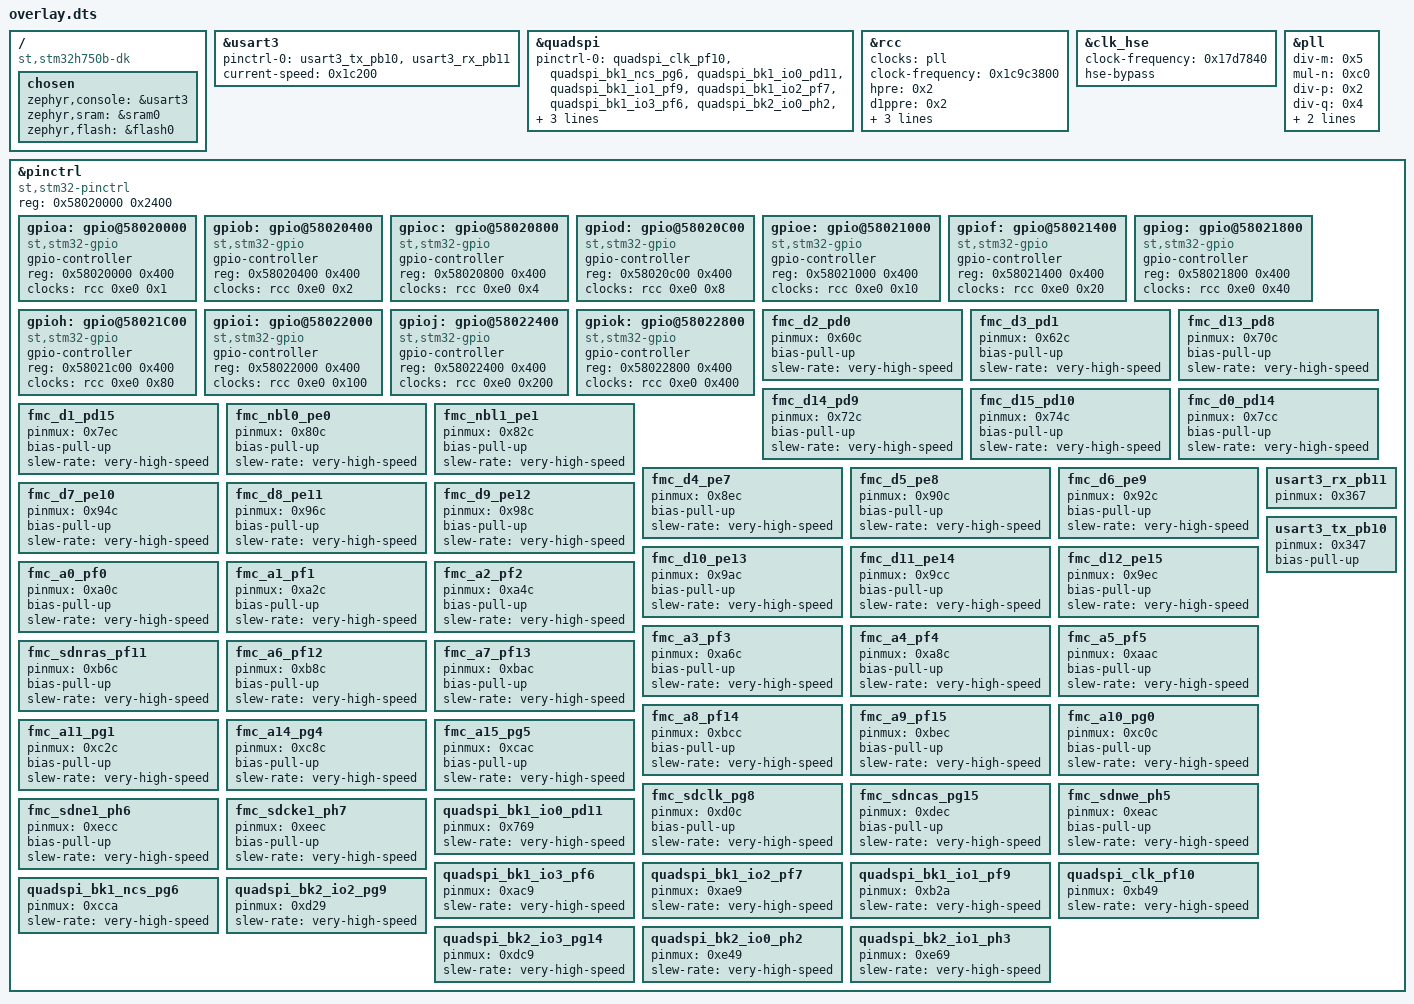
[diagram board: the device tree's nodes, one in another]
/ {
	compatible = "st,stm32h750b-dk";
	chosen {
		zephyr,console = &usart3;
		zephyr,sram = &sram0;
		zephyr,flash = &flash0;
	};
};
&usart3{
	status = "okay";
	pinctrl-0 = < &usart3_tx_pb10 &usart3_rx_pb11 >;
	pinctrl-names = "default";
	current-speed = < 0x1c200 >;
};
&quadspi{
	status = "okay";
	pinctrl-names = "default";
	pinctrl-0 = < &quadspi_clk_pf10 &quadspi_bk1_ncs_pg6 &quadspi_bk1_io0_pd11 &quadspi_bk1_io1_pf9 &quadspi_bk1_io2_pf7 &quadspi_bk1_io3_pf6 &quadspi_bk2_io0_ph2 &quadspi_bk2_io1_ph3 &quadspi_bk2_io2_pg9 &quadspi_bk2_io3_pg14 >;
	flash-id = < 0x1 >;
};
&rcc{
	clocks = < &pll >;
	clock-frequency = < 0x1c9c3800 >;
	hpre = < 0x2 >;
	d1ppre = < 0x2 >;
	d2ppre1 = < 0x2 >;
	d2ppre2 = < 0x2 >;
	d3ppre = < 0x2 >;
};
&clk_hse{
	status = "okay";
	clock-frequency = < 0x17d7840 >;
	hse-bypass;
};
&pll{
	status = "okay";
	div-m = < 0x5 >;
	mul-n = < 0xc0 >;
	div-p = < 0x2 >;
	div-q = < 0x4 >;
	div-r = < 0x4 >;
	clocks = < &clk_hse >;
};
&pinctrl{
	compatible = "st,stm32-pinctrl";
	#address-cells = < 0x1 >;
	#size-cells = < 0x1 >;
	reg = < 0x58020000 0x2400 >;
	gpioa: gpio@58020000 {
		compatible = "st,stm32-gpio";
		gpio-controller;
		#gpio-cells = < 0x2 >;
		reg = < 0x58020000 0x400 >;
		clocks = < &rcc 0xe0 0x1 >;
	};
	gpiob: gpio@58020400 {
		compatible = "st,stm32-gpio";
		gpio-controller;
		#gpio-cells = < 0x2 >;
		reg = < 0x58020400 0x400 >;
		clocks = < &rcc 0xe0 0x2 >;
	};
	gpioc: gpio@58020800 {
		compatible = "st,stm32-gpio";
		gpio-controller;
		#gpio-cells = < 0x2 >;
		reg = < 0x58020800 0x400 >;
		clocks = < &rcc 0xe0 0x4 >;
	};
	gpiod: gpio@58020C00 {
		compatible = "st,stm32-gpio";
		gpio-controller;
		#gpio-cells = < 0x2 >;
		reg = < 0x58020c00 0x400 >;
		clocks = < &rcc 0xe0 0x8 >;
	};
	gpioe: gpio@58021000 {
		compatible = "st,stm32-gpio";
		gpio-controller;
		#gpio-cells = < 0x2 >;
		reg = < 0x58021000 0x400 >;
		clocks = < &rcc 0xe0 0x10 >;
	};
	gpiof: gpio@58021400 {
		compatible = "st,stm32-gpio";
		gpio-controller;
		#gpio-cells = < 0x2 >;
		reg = < 0x58021400 0x400 >;
		clocks = < &rcc 0xe0 0x20 >;
	};
	gpiog: gpio@58021800 {
		compatible = "st,stm32-gpio";
		gpio-controller;
		#gpio-cells = < 0x2 >;
		reg = < 0x58021800 0x400 >;
		clocks = < &rcc 0xe0 0x40 >;
	};
	gpioh: gpio@58021C00 {
		compatible = "st,stm32-gpio";
		gpio-controller;
		#gpio-cells = < 0x2 >;
		reg = < 0x58021c00 0x400 >;
		clocks = < &rcc 0xe0 0x80 >;
	};
	gpioi: gpio@58022000 {
		compatible = "st,stm32-gpio";
		gpio-controller;
		#gpio-cells = < 0x2 >;
		reg = < 0x58022000 0x400 >;
		clocks = < &rcc 0xe0 0x100 >;
	};
	gpioj: gpio@58022400 {
		compatible = "st,stm32-gpio";
		gpio-controller;
		#gpio-cells = < 0x2 >;
		reg = < 0x58022400 0x400 >;
		clocks = < &rcc 0xe0 0x200 >;
	};
	gpiok: gpio@58022800 {
		compatible = "st,stm32-gpio";
		gpio-controller;
		#gpio-cells = < 0x2 >;
		reg = < 0x58022800 0x400 >;
		clocks = < &rcc 0xe0 0x400 >;
	};
	fmc_d2_pd0: fmc_d2_pd0 {
		pinmux = < 0x60c >;
		bias-pull-up;
		slew-rate = "very-high-speed";
	};
	fmc_d3_pd1: fmc_d3_pd1 {
		pinmux = < 0x62c >;
		bias-pull-up;
		slew-rate = "very-high-speed";
	};
	fmc_d13_pd8: fmc_d13_pd8 {
		pinmux = < 0x70c >;
		bias-pull-up;
		slew-rate = "very-high-speed";
	};
	fmc_d14_pd9: fmc_d14_pd9 {
		pinmux = < 0x72c >;
		bias-pull-up;
		slew-rate = "very-high-speed";
	};
	fmc_d15_pd10: fmc_d15_pd10 {
		pinmux = < 0x74c >;
		bias-pull-up;
		slew-rate = "very-high-speed";
	};
	fmc_d0_pd14: fmc_d0_pd14 {
		pinmux = < 0x7cc >;
		bias-pull-up;
		slew-rate = "very-high-speed";
	};
	fmc_d1_pd15: fmc_d1_pd15 {
		pinmux = < 0x7ec >;
		bias-pull-up;
		slew-rate = "very-high-speed";
	};
	fmc_nbl0_pe0: fmc_nbl0_pe0 {
		pinmux = < 0x80c >;
		bias-pull-up;
		slew-rate = "very-high-speed";
	};
	fmc_nbl1_pe1: fmc_nbl1_pe1 {
		pinmux = < 0x82c >;
		bias-pull-up;
		slew-rate = "very-high-speed";
	};
	fmc_d4_pe7: fmc_d4_pe7 {
		pinmux = < 0x8ec >;
		bias-pull-up;
		slew-rate = "very-high-speed";
	};
	fmc_d5_pe8: fmc_d5_pe8 {
		pinmux = < 0x90c >;
		bias-pull-up;
		slew-rate = "very-high-speed";
	};
	fmc_d6_pe9: fmc_d6_pe9 {
		pinmux = < 0x92c >;
		bias-pull-up;
		slew-rate = "very-high-speed";
	};
	fmc_d7_pe10: fmc_d7_pe10 {
		pinmux = < 0x94c >;
		bias-pull-up;
		slew-rate = "very-high-speed";
	};
	fmc_d8_pe11: fmc_d8_pe11 {
		pinmux = < 0x96c >;
		bias-pull-up;
		slew-rate = "very-high-speed";
	};
	fmc_d9_pe12: fmc_d9_pe12 {
		pinmux = < 0x98c >;
		bias-pull-up;
		slew-rate = "very-high-speed";
	};
	fmc_d10_pe13: fmc_d10_pe13 {
		pinmux = < 0x9ac >;
		bias-pull-up;
		slew-rate = "very-high-speed";
	};
	fmc_d11_pe14: fmc_d11_pe14 {
		pinmux = < 0x9cc >;
		bias-pull-up;
		slew-rate = "very-high-speed";
	};
	fmc_d12_pe15: fmc_d12_pe15 {
		pinmux = < 0x9ec >;
		bias-pull-up;
		slew-rate = "very-high-speed";
	};
	fmc_a0_pf0: fmc_a0_pf0 {
		pinmux = < 0xa0c >;
		bias-pull-up;
		slew-rate = "very-high-speed";
	};
	fmc_a1_pf1: fmc_a1_pf1 {
		pinmux = < 0xa2c >;
		bias-pull-up;
		slew-rate = "very-high-speed";
	};
	fmc_a2_pf2: fmc_a2_pf2 {
		pinmux = < 0xa4c >;
		bias-pull-up;
		slew-rate = "very-high-speed";
	};
	fmc_a3_pf3: fmc_a3_pf3 {
		pinmux = < 0xa6c >;
		bias-pull-up;
		slew-rate = "very-high-speed";
	};
	fmc_a4_pf4: fmc_a4_pf4 {
		pinmux = < 0xa8c >;
		bias-pull-up;
		slew-rate = "very-high-speed";
	};
	fmc_a5_pf5: fmc_a5_pf5 {
		pinmux = < 0xaac >;
		bias-pull-up;
		slew-rate = "very-high-speed";
	};
	fmc_sdnras_pf11: fmc_sdnras_pf11 {
		pinmux = < 0xb6c >;
		bias-pull-up;
		slew-rate = "very-high-speed";
	};
	fmc_a6_pf12: fmc_a6_pf12 {
		pinmux = < 0xb8c >;
		bias-pull-up;
		slew-rate = "very-high-speed";
	};
	fmc_a7_pf13: fmc_a7_pf13 {
		pinmux = < 0xbac >;
		bias-pull-up;
		slew-rate = "very-high-speed";
	};
	fmc_a8_pf14: fmc_a8_pf14 {
		pinmux = < 0xbcc >;
		bias-pull-up;
		slew-rate = "very-high-speed";
	};
	fmc_a9_pf15: fmc_a9_pf15 {
		pinmux = < 0xbec >;
		bias-pull-up;
		slew-rate = "very-high-speed";
	};
	fmc_a10_pg0: fmc_a10_pg0 {
		pinmux = < 0xc0c >;
		bias-pull-up;
		slew-rate = "very-high-speed";
	};
	fmc_a11_pg1: fmc_a11_pg1 {
		pinmux = < 0xc2c >;
		bias-pull-up;
		slew-rate = "very-high-speed";
	};
	fmc_a14_pg4: fmc_a14_pg4 {
		pinmux = < 0xc8c >;
		bias-pull-up;
		slew-rate = "very-high-speed";
	};
	fmc_a15_pg5: fmc_a15_pg5 {
		pinmux = < 0xcac >;
		bias-pull-up;
		slew-rate = "very-high-speed";
	};
	fmc_sdclk_pg8: fmc_sdclk_pg8 {
		pinmux = < 0xd0c >;
		bias-pull-up;
		slew-rate = "very-high-speed";
	};
	fmc_sdncas_pg15: fmc_sdncas_pg15 {
		pinmux = < 0xdec >;
		bias-pull-up;
		slew-rate = "very-high-speed";
	};
	fmc_sdnwe_ph5: fmc_sdnwe_ph5 {
		pinmux = < 0xeac >;
		bias-pull-up;
		slew-rate = "very-high-speed";
	};
	fmc_sdne1_ph6: fmc_sdne1_ph6 {
		pinmux = < 0xecc >;
		bias-pull-up;
		slew-rate = "very-high-speed";
	};
	fmc_sdcke1_ph7: fmc_sdcke1_ph7 {
		pinmux = < 0xeec >;
		bias-pull-up;
		slew-rate = "very-high-speed";
	};
	quadspi_bk1_io0_pd11: quadspi_bk1_io0_pd11 {
		pinmux = < 0x769 >;
		slew-rate = "very-high-speed";
	};
	quadspi_bk1_io3_pf6: quadspi_bk1_io3_pf6 {
		pinmux = < 0xac9 >;
		slew-rate = "very-high-speed";
	};
	quadspi_bk1_io2_pf7: quadspi_bk1_io2_pf7 {
		pinmux = < 0xae9 >;
		slew-rate = "very-high-speed";
	};
	quadspi_bk1_io1_pf9: quadspi_bk1_io1_pf9 {
		pinmux = < 0xb2a >;
		slew-rate = "very-high-speed";
	};
	quadspi_clk_pf10: quadspi_clk_pf10 {
		pinmux = < 0xb49 >;
		slew-rate = "very-high-speed";
	};
	quadspi_bk1_ncs_pg6: quadspi_bk1_ncs_pg6 {
		pinmux = < 0xcca >;
		slew-rate = "very-high-speed";
	};
	quadspi_bk2_io2_pg9: quadspi_bk2_io2_pg9 {
		pinmux = < 0xd29 >;
		slew-rate = "very-high-speed";
	};
	quadspi_bk2_io3_pg14: quadspi_bk2_io3_pg14 {
		pinmux = < 0xdc9 >;
		slew-rate = "very-high-speed";
	};
	quadspi_bk2_io0_ph2: quadspi_bk2_io0_ph2 {
		pinmux = < 0xe49 >;
		slew-rate = "very-high-speed";
	};
	quadspi_bk2_io1_ph3: quadspi_bk2_io1_ph3 {
		pinmux = < 0xe69 >;
		slew-rate = "very-high-speed";
	};
	usart3_rx_pb11: usart3_rx_pb11 {
		pinmux = < 0x367 >;
	};
	usart3_tx_pb10: usart3_tx_pb10 {
		pinmux = < 0x347 >;
		bias-pull-up;
	};
};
